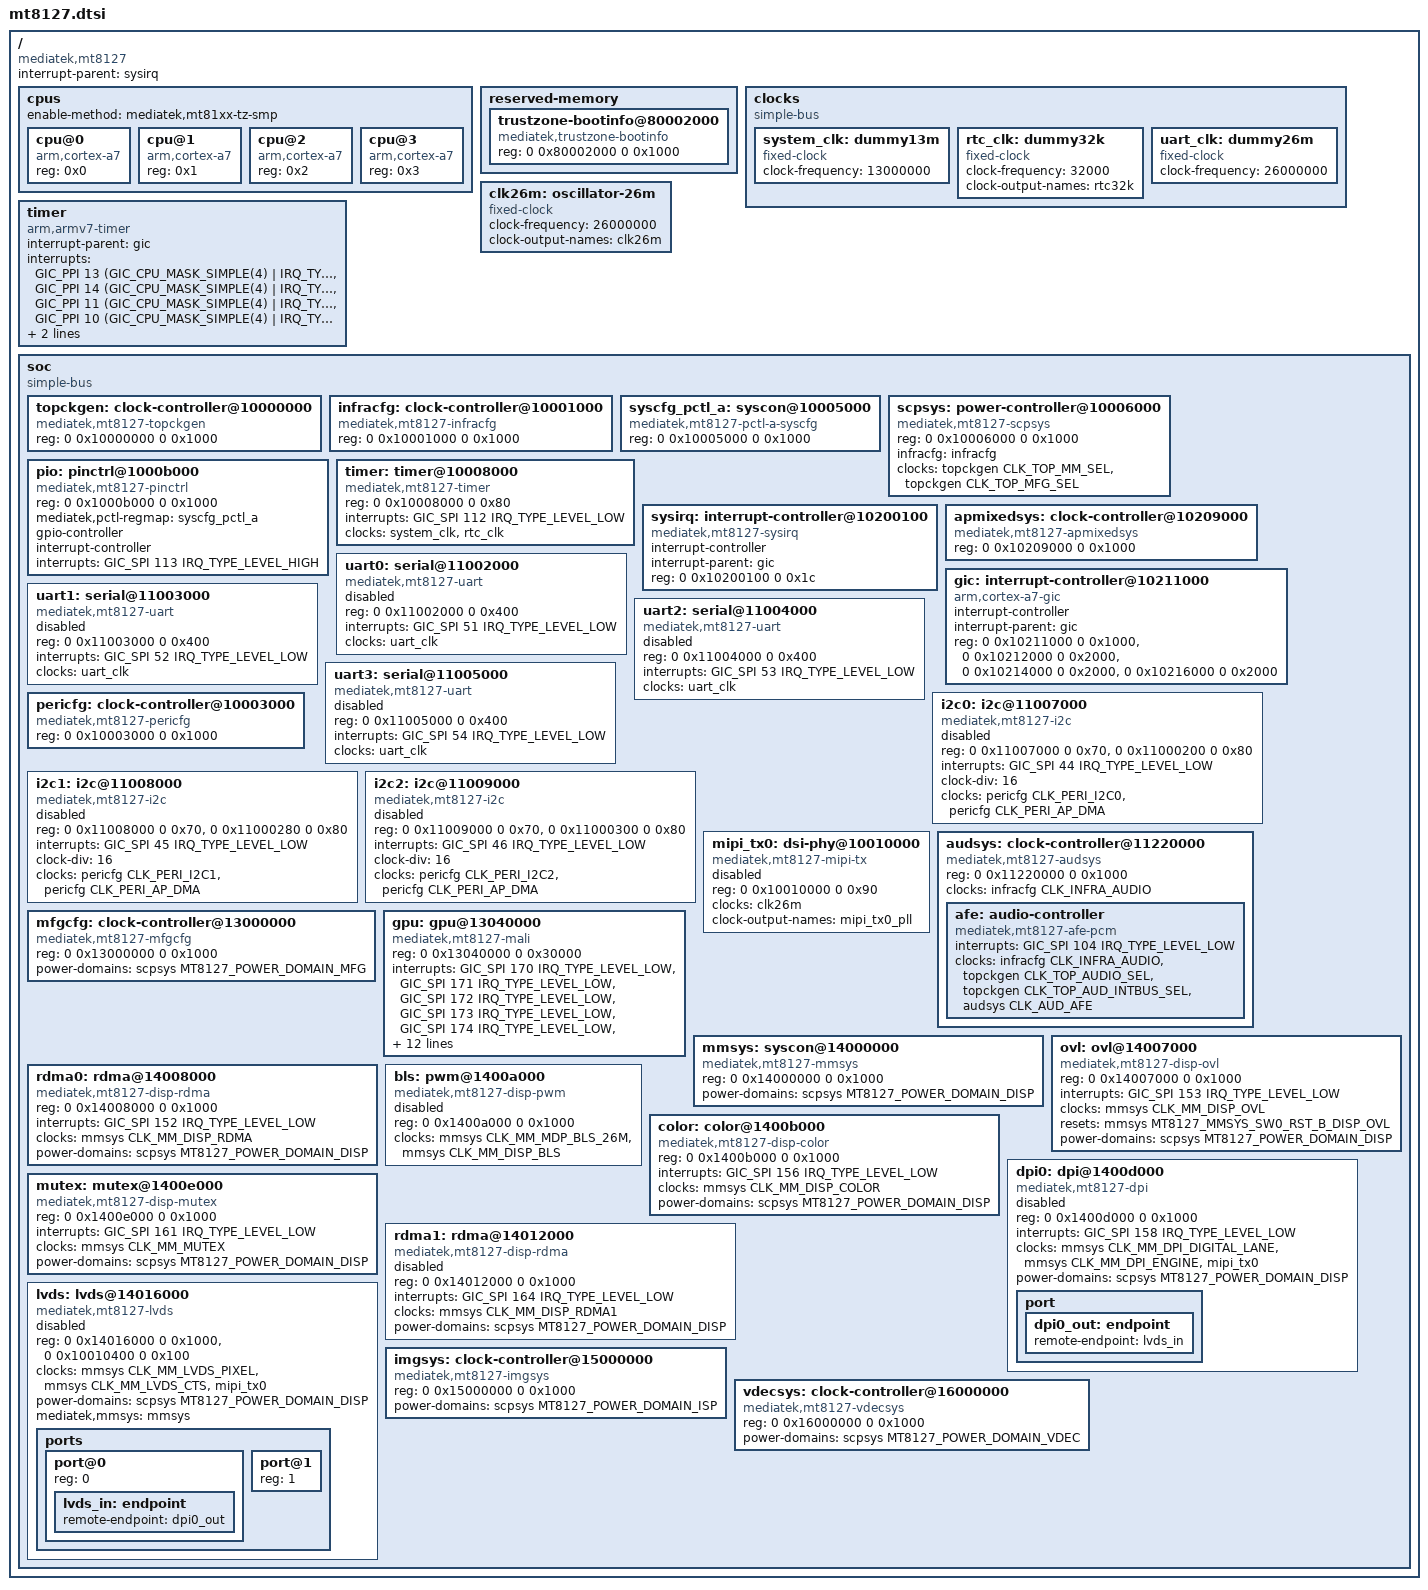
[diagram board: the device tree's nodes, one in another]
// SPDX-License-Identifier: GPL-2.0
/*
 * Copyright (c) 2014 MediaTek Inc.
 * Author: Joe.C <yingjoe.chen@mediatek.com>
 *
 */

#include <dt-bindings/clock/mt8127-clk.h>
#include <dt-bindings/interrupt-controller/irq.h>
#include <dt-bindings/interrupt-controller/arm-gic.h>
#include <dt-bindings/power/mediatek,mt8127-power.h>
#include <dt-bindings/reset/mt8127-resets.h>

/ {
	#address-cells = <2>;
	#size-cells = <2>;
	compatible = "mediatek,mt8127";
	interrupt-parent = <&sysirq>;

	cpus {
		#address-cells = <1>;
		#size-cells = <0>;
		enable-method = "mediatek,mt81xx-tz-smp";

		cpu@0 {
			device_type = "cpu";
			compatible = "arm,cortex-a7";
			reg = <0x0>;
		};
		cpu@1 {
			device_type = "cpu";
			compatible = "arm,cortex-a7";
			reg = <0x1>;
		};
		cpu@2 {
			device_type = "cpu";
			compatible = "arm,cortex-a7";
			reg = <0x2>;
		};
		cpu@3 {
			device_type = "cpu";
			compatible = "arm,cortex-a7";
			reg = <0x3>;
		};

	};

	reserved-memory {
		#address-cells = <2>;
		#size-cells = <2>;
		ranges;

		trustzone-bootinfo@80002000 {
			compatible = "mediatek,trustzone-bootinfo";
			reg = <0 0x80002000 0 0x1000>;
		};
	};

	clocks {
		#address-cells = <2>;
		#size-cells = <2>;
		compatible = "simple-bus";
		ranges;

		system_clk: dummy13m {
			compatible = "fixed-clock";
			clock-frequency = <13000000>;
			#clock-cells = <0>;
		};

		rtc_clk: dummy32k {
			compatible = "fixed-clock";
			clock-frequency = <32000>;
			#clock-cells = <0>;
			clock-output-names = "rtc32k";
		};

		uart_clk: dummy26m {
			compatible = "fixed-clock";
			clock-frequency = <26000000>;
			#clock-cells = <0>;
                };
	};

	clk26m: oscillator-26m {
		compatible = "fixed-clock";
		#clock-cells = <0>;
		clock-frequency = <26000000>;
		clock-output-names = "clk26m";
	};

	timer {
		compatible = "arm,armv7-timer";
		interrupt-parent = <&gic>;
		interrupts = <GIC_PPI 13 (GIC_CPU_MASK_SIMPLE(4) |
					  IRQ_TYPE_LEVEL_LOW)>,
			     <GIC_PPI 14 (GIC_CPU_MASK_SIMPLE(4) |
					  IRQ_TYPE_LEVEL_LOW)>,
			     <GIC_PPI 11 (GIC_CPU_MASK_SIMPLE(4) |
					  IRQ_TYPE_LEVEL_LOW)>,
			     <GIC_PPI 10 (GIC_CPU_MASK_SIMPLE(4) |
					  IRQ_TYPE_LEVEL_LOW)>;
		clock-frequency = <13000000>;
		arm,cpu-registers-not-fw-configured;
	};

	soc {
		#address-cells = <2>;
		#size-cells = <2>;
		compatible = "simple-bus";
		ranges;

		topckgen: clock-controller@10000000 {
			compatible = "mediatek,mt8127-topckgen", "syscon";
			reg = <0 0x10000000 0 0x1000>;
			#clock-cells = <1>;
		};

		infracfg: clock-controller@10001000 {
			compatible = "mediatek,mt8127-infracfg", "syscon";
			reg = <0 0x10001000 0 0x1000>;
			#clock-cells = <1>;
		};

		syscfg_pctl_a: syscon@10005000 {
			compatible = "mediatek,mt8127-pctl-a-syscfg", "syscon";
			reg = <0 0x10005000 0 0x1000>;
		};

		scpsys: power-controller@10006000 {
			compatible = "mediatek,mt8127-scpsys", "syscon";
			reg = <0 0x10006000 0 0x1000>;
			#power-domain-cells = <1>;
			infracfg = <&infracfg>;
			clocks = <&topckgen CLK_TOP_MM_SEL>,
				 <&topckgen CLK_TOP_MFG_SEL>;
			clock-names = "mm", "mfg";
		};

		pio: pinctrl@1000b000 {
			compatible = "mediatek,mt8127-pinctrl";
			reg = <0 0x1000b000 0 0x1000>;
			mediatek,pctl-regmap = <&syscfg_pctl_a>;
			gpio-controller;
			#gpio-cells = <2>;
			interrupt-controller;
			#interrupt-cells = <2>;
			interrupts = <GIC_SPI 113 IRQ_TYPE_LEVEL_HIGH>;
		};

		timer: timer@10008000 {
			compatible = "mediatek,mt8127-timer",
					"mediatek,mt6577-timer";
			reg = <0 0x10008000 0 0x80>;
			interrupts = <GIC_SPI 112 IRQ_TYPE_LEVEL_LOW>;
			clocks = <&system_clk>, <&rtc_clk>;
			clock-names = "system-clk", "rtc-clk";
		};

		sysirq: interrupt-controller@10200100 {
			compatible = "mediatek,mt8127-sysirq",
				     "mediatek,mt6577-sysirq";
			interrupt-controller;
			#interrupt-cells = <3>;
			interrupt-parent = <&gic>;
			reg = <0 0x10200100 0 0x1c>;
		};

		apmixedsys: clock-controller@10209000 {
			compatible = "mediatek,mt8127-apmixedsys";
			reg = <0 0x10209000 0 0x1000>;
			#clock-cells = <1>;
		};

		gic: interrupt-controller@10211000 {
			compatible = "arm,cortex-a7-gic";
			interrupt-controller;
			#interrupt-cells = <3>;
			interrupt-parent = <&gic>;
			reg = <0 0x10211000 0 0x1000>,
			      <0 0x10212000 0 0x2000>,
			      <0 0x10214000 0 0x2000>,
			      <0 0x10216000 0 0x2000>;
		};

		uart0: serial@11002000 {
			compatible = "mediatek,mt8127-uart","mediatek,mt6577-uart";
			reg = <0 0x11002000 0 0x400>;
			interrupts = <GIC_SPI 51 IRQ_TYPE_LEVEL_LOW>;
			clocks = <&uart_clk>;
			status = "disabled";
		};

		uart1: serial@11003000 {
			compatible = "mediatek,mt8127-uart","mediatek,mt6577-uart";
			reg = <0 0x11003000 0 0x400>;
			interrupts = <GIC_SPI 52 IRQ_TYPE_LEVEL_LOW>;
			clocks = <&uart_clk>;
			status = "disabled";
		};

		uart2: serial@11004000 {
			compatible = "mediatek,mt8127-uart","mediatek,mt6577-uart";
			reg = <0 0x11004000 0 0x400>;
			interrupts = <GIC_SPI 53 IRQ_TYPE_LEVEL_LOW>;
			clocks = <&uart_clk>;
			status = "disabled";
		};

		uart3: serial@11005000 {
			compatible = "mediatek,mt8127-uart","mediatek,mt6577-uart";
			reg = <0 0x11005000 0 0x400>;
			interrupts = <GIC_SPI 54 IRQ_TYPE_LEVEL_LOW>;
			clocks = <&uart_clk>;
			status = "disabled";
		};

		pericfg: clock-controller@10003000 {
			compatible = "mediatek,mt8127-pericfg", "syscon";
			reg = <0 0x10003000 0 0x1000>;
			#clock-cells = <1>;
		};

		i2c0: i2c@11007000 {
			compatible = "mediatek,mt8127-i2c", "mediatek,mt6577-i2c";
			reg = <0 0x11007000 0 0x70>,
			      <0 0x11000200 0 0x80>;
			interrupts = <GIC_SPI 44 IRQ_TYPE_LEVEL_LOW>;
			clock-div = <16>;
			clocks = <&pericfg CLK_PERI_I2C0>, <&pericfg CLK_PERI_AP_DMA>;
			clock-names = "main", "dma";
			#address-cells = <1>;
			#size-cells = <0>;
			status = "disabled";
		};

		i2c1: i2c@11008000 {
			compatible = "mediatek,mt8127-i2c", "mediatek,mt6577-i2c";
			reg = <0 0x11008000 0 0x70>,
			      <0 0x11000280 0 0x80>;
			interrupts = <GIC_SPI 45 IRQ_TYPE_LEVEL_LOW>;
			clock-div = <16>;
			clocks = <&pericfg CLK_PERI_I2C1>, <&pericfg CLK_PERI_AP_DMA>;
			clock-names = "main", "dma";
			#address-cells = <1>;
			#size-cells = <0>;
			status = "disabled";
		};

		i2c2: i2c@11009000 {
			compatible = "mediatek,mt8127-i2c", "mediatek,mt6577-i2c";
			reg = <0 0x11009000 0 0x70>,
			      <0 0x11000300 0 0x80>;
			interrupts = <GIC_SPI 46 IRQ_TYPE_LEVEL_LOW>;
			clock-div = <16>;
			clocks = <&pericfg CLK_PERI_I2C2>, <&pericfg CLK_PERI_AP_DMA>;
			clock-names = "main", "dma";
			#address-cells = <1>;
			#size-cells = <0>;
			status = "disabled";
		};

		mipi_tx0: dsi-phy@10010000 {
			compatible = "mediatek,mt8127-mipi-tx";
			reg = <0 0x10010000 0 0x90>;
			clocks = <&clk26m>;
			clock-output-names = "mipi_tx0_pll";
			#clock-cells = <0>;
			#phy-cells = <0>;
			status = "disabled";
		};

		audsys: clock-controller@11220000 {
			compatible = "mediatek,mt8127-audsys", "syscon";
			reg = <0 0x11220000 0 0x1000>;
			#clock-cells = <1>;
			clocks = <&infracfg CLK_INFRA_AUDIO>;

			afe: audio-controller {
				compatible = "mediatek,mt8127-afe-pcm";
				interrupts = <GIC_SPI 104 IRQ_TYPE_LEVEL_LOW>;
				clocks = <&infracfg CLK_INFRA_AUDIO>,
					 <&topckgen CLK_TOP_AUDIO_SEL>,
					 <&topckgen CLK_TOP_AUD_INTBUS_SEL>,
					 <&audsys CLK_AUD_AFE>;
				clock-names = "infra_sys_audio_clk", "top_pdn_audio",
					      "top_pdn_aud_intbus", "aud_afe";
			};
		};

		mfgcfg: clock-controller@13000000 {
			compatible = "mediatek,mt8127-mfgcfg", "syscon";
			reg = <0 0x13000000 0 0x1000>;
			#clock-cells = <1>;
			power-domains = <&scpsys MT8127_POWER_DOMAIN_MFG>;
		};

		/*
		 * Mali-450 MP4. The GPU reaches the DRAM through the multimedia SMI,
		 * which serves as its bus clock. The core clock runs from UNIVPLL / 3
		 * (416 MHz), as with the stock kernel.
		 */
		gpu: gpu@13040000 {
			compatible = "mediatek,mt8127-mali", "arm,mali-450";
			reg = <0 0x13040000 0 0x30000>;
			interrupts = <GIC_SPI 170 IRQ_TYPE_LEVEL_LOW>,
				     <GIC_SPI 171 IRQ_TYPE_LEVEL_LOW>,
				     <GIC_SPI 172 IRQ_TYPE_LEVEL_LOW>,
				     <GIC_SPI 173 IRQ_TYPE_LEVEL_LOW>,
				     <GIC_SPI 174 IRQ_TYPE_LEVEL_LOW>,
				     <GIC_SPI 175 IRQ_TYPE_LEVEL_LOW>,
				     <GIC_SPI 176 IRQ_TYPE_LEVEL_LOW>,
				     <GIC_SPI 177 IRQ_TYPE_LEVEL_LOW>,
				     <GIC_SPI 178 IRQ_TYPE_LEVEL_LOW>,
				     <GIC_SPI 179 IRQ_TYPE_LEVEL_LOW>,
				     <GIC_SPI 180 IRQ_TYPE_LEVEL_LOW>;
			interrupt-names = "gp", "gpmmu", "pp0", "ppmmu0", "pp1",
					  "ppmmu1", "pp2", "ppmmu2", "pp3", "ppmmu3",
					  "pp";
			clocks = <&mmsys CLK_MM_SMI_COMMON>, <&mfgcfg CLK_MFG_G3D>;
			clock-names = "bus", "core";
			assigned-clocks = <&topckgen CLK_TOP_MFG_SEL>;
			assigned-clock-parents = <&topckgen CLK_TOP_UNIVPLL_D3>;
			power-domains = <&scpsys MT8127_POWER_DOMAIN_MFG>;
		};

		mmsys: syscon@14000000 {
			compatible = "mediatek,mt8127-mmsys", "syscon";
			reg = <0 0x14000000 0 0x1000>;
			#clock-cells = <1>;
			#reset-cells = <1>;
			power-domains = <&scpsys MT8127_POWER_DOMAIN_DISP>;
		};

		ovl: ovl@14007000 {
			compatible = "mediatek,mt8127-disp-ovl",
				     "mediatek,mt2701-disp-ovl";
			reg = <0 0x14007000 0 0x1000>;
			interrupts = <GIC_SPI 153 IRQ_TYPE_LEVEL_LOW>;
			clocks = <&mmsys CLK_MM_DISP_OVL>;
			resets = <&mmsys MT8127_MMSYS_SW0_RST_B_DISP_OVL>;
			power-domains = <&scpsys MT8127_POWER_DOMAIN_DISP>;
		};

		rdma0: rdma@14008000 {
			compatible = "mediatek,mt8127-disp-rdma",
				     "mediatek,mt2701-disp-rdma";
			reg = <0 0x14008000 0 0x1000>;
			interrupts = <GIC_SPI 152 IRQ_TYPE_LEVEL_LOW>;
			clocks = <&mmsys CLK_MM_DISP_RDMA>;
			power-domains = <&scpsys MT8127_POWER_DOMAIN_DISP>;
		};

		bls: pwm@1400a000 {
			compatible = "mediatek,mt8127-disp-pwm",
				     "mediatek,mt2701-disp-pwm";
			reg = <0 0x1400a000 0 0x1000>;
			#pwm-cells = <2>;
			clocks = <&mmsys CLK_MM_MDP_BLS_26M>,
				 <&mmsys CLK_MM_DISP_BLS>;
			clock-names = "main", "mm";
			status = "disabled";
		};

		color: color@1400b000 {
			compatible = "mediatek,mt8127-disp-color",
				     "mediatek,mt2701-disp-color";
			reg = <0 0x1400b000 0 0x1000>;
			interrupts = <GIC_SPI 156 IRQ_TYPE_LEVEL_LOW>;
			clocks = <&mmsys CLK_MM_DISP_COLOR>;
			power-domains = <&scpsys MT8127_POWER_DOMAIN_DISP>;
		};

		dpi0: dpi@1400d000 {
			compatible = "mediatek,mt8127-dpi";
			reg = <0 0x1400d000 0 0x1000>;
			interrupts = <GIC_SPI 158 IRQ_TYPE_LEVEL_LOW>;
			clocks = <&mmsys CLK_MM_DPI_DIGITAL_LANE>,
				 <&mmsys CLK_MM_DPI_ENGINE>,
				 <&mipi_tx0>;
			clock-names = "pixel", "engine", "pll";
			power-domains = <&scpsys MT8127_POWER_DOMAIN_DISP>;
			status = "disabled";

			port {
				dpi0_out: endpoint {
					remote-endpoint = <&lvds_in>;
				};
			};
		};

		mutex: mutex@1400e000 {
			compatible = "mediatek,mt8127-disp-mutex";
			reg = <0 0x1400e000 0 0x1000>;
			interrupts = <GIC_SPI 161 IRQ_TYPE_LEVEL_LOW>;
			clocks = <&mmsys CLK_MM_MUTEX>;
			power-domains = <&scpsys MT8127_POWER_DOMAIN_DISP>;
		};

		rdma1: rdma@14012000 {
			compatible = "mediatek,mt8127-disp-rdma",
				     "mediatek,mt2701-disp-rdma";
			reg = <0 0x14012000 0 0x1000>;
			interrupts = <GIC_SPI 164 IRQ_TYPE_LEVEL_LOW>;
			clocks = <&mmsys CLK_MM_DISP_RDMA1>;
			power-domains = <&scpsys MT8127_POWER_DOMAIN_DISP>;
			status = "disabled";
		};

		lvds: lvds@14016000 {
			compatible = "mediatek,mt8127-lvds";
			reg = <0 0x14016000 0 0x1000>,
			      <0 0x10010400 0 0x100>;
			reg-names = "tx", "ana";
			clocks = <&mmsys CLK_MM_LVDS_PIXEL>,
				 <&mmsys CLK_MM_LVDS_CTS>,
				 <&mipi_tx0>;
			clock-names = "pixel", "cts", "pll";
			power-domains = <&scpsys MT8127_POWER_DOMAIN_DISP>;
			mediatek,mmsys = <&mmsys>;
			status = "disabled";

			ports {
				#address-cells = <1>;
				#size-cells = <0>;

				port@0 {
					reg = <0>;

					lvds_in: endpoint {
						remote-endpoint = <&dpi0_out>;
					};
				};

				port@1 {
					reg = <1>;
				};
			};
		};

		imgsys: clock-controller@15000000 {
			compatible = "mediatek,mt8127-imgsys", "syscon";
			reg = <0 0x15000000 0 0x1000>;
			#clock-cells = <1>;
			power-domains = <&scpsys MT8127_POWER_DOMAIN_ISP>;
		};

		vdecsys: clock-controller@16000000 {
			compatible = "mediatek,mt8127-vdecsys", "syscon";
			reg = <0 0x16000000 0 0x1000>;
			#clock-cells = <1>;
			power-domains = <&scpsys MT8127_POWER_DOMAIN_VDEC>;
		};
	};
};
